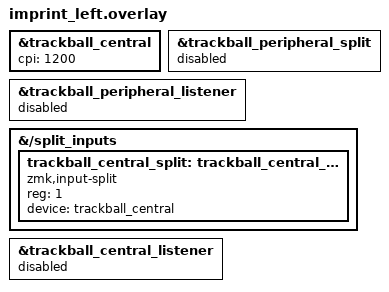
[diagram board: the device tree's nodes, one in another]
&trackball_central {
    cpi = <1200>;
};

&trackball_peripheral_split {
    status = "disabled";
};

&trackball_peripheral_listener {
    status = "disabled";
};

&{/split_inputs} {
    trackball_central_split: trackball_central_split@1 {
        compatible = "zmk,input-split";
        reg = <1>;
        device = <&trackball_central>;
    };
};

&trackball_central_listener {
    status = "disabled";
};
